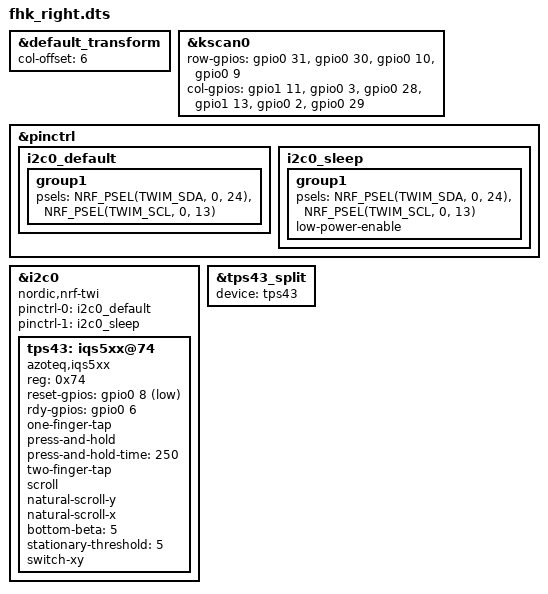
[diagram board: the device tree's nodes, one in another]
/*
*
* Copyright (c) 2024 The ZMK Contributors
* SPDX-License-Identifier: MIT
*
*/

#include "fhk.dtsi"

&default_transform {
    col-offset = <6>;
};

&kscan0 {
    row-gpios
        = <&gpio0 31 (GPIO_ACTIVE_HIGH | GPIO_PULL_DOWN)>
        , <&gpio0 30 (GPIO_ACTIVE_HIGH | GPIO_PULL_DOWN)>
        , <&gpio0 10 (GPIO_ACTIVE_HIGH | GPIO_PULL_DOWN)>
        , <&gpio0 9 (GPIO_ACTIVE_HIGH | GPIO_PULL_DOWN)>
        ;
    col-gpios
        = <&gpio1 11 GPIO_ACTIVE_HIGH>
        , <&gpio0 3 GPIO_ACTIVE_HIGH>
        , <&gpio0 28 GPIO_ACTIVE_HIGH>
        , <&gpio1 13 GPIO_ACTIVE_HIGH>
        , <&gpio0 2 GPIO_ACTIVE_HIGH>
        , <&gpio0 29 GPIO_ACTIVE_HIGH>
        ;
};

&pinctrl {
    i2c0_default: i2c0_default {
        group1 {
            psels = <NRF_PSEL(TWIM_SDA, 0, 24)>,
                <NRF_PSEL(TWIM_SCL, 0, 13)>;
        };
    };

    i2c0_sleep: i2c0_sleep {
        group1 {
            psels = <NRF_PSEL(TWIM_SDA, 0, 24)>,
                <NRF_PSEL(TWIM_SCL, 0, 13)>;
            low-power-enable;
        };
    };
};

&i2c0 {
    status = "okay";
    compatible = "nordic,nrf-twi";
	pinctrl-0 = <&i2c0_default>;
	pinctrl-1 = <&i2c0_sleep>;
	pinctrl-names = "default", "sleep";
    tps43: iqs5xx@74 {
        status = "okay";
        compatible = "azoteq,iqs5xx";
        reg = <0x74>;

        reset-gpios = <&gpio0 8 GPIO_ACTIVE_LOW>;
        rdy-gpios = <&gpio0 6 GPIO_ACTIVE_HIGH>;

        /*
         * Potentially non-exhaustive list of configuration options.
         * See: dts/bindings/input/azoteq,iqs5xx-common.yaml for a full list.
         */
        one-finger-tap;
        press-and-hold;
        press-and-hold-time = <250>;
        two-finger-tap;

        scroll;
        natural-scroll-y;
        natural-scroll-x;

        bottom-beta = <5>;
        stationary-threshold = <5>;

        switch-xy;
    };
};

&tps43_split {
    device = <&tps43>;
};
